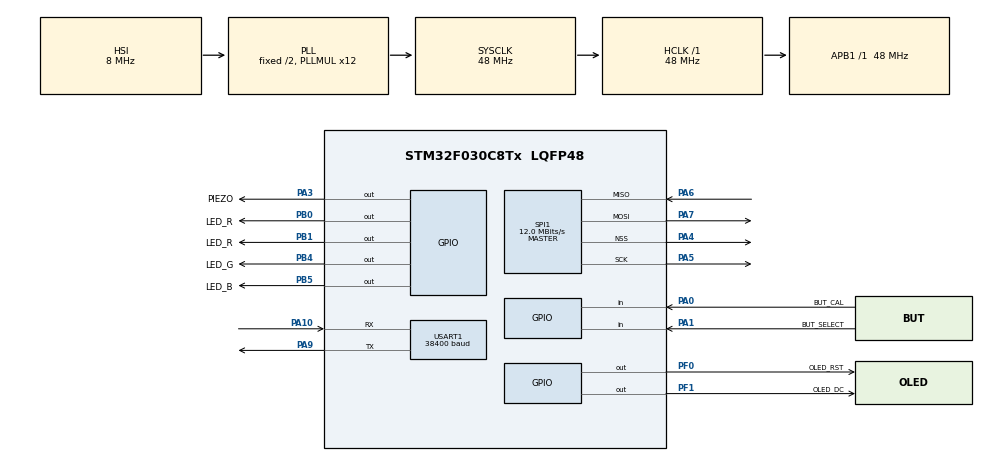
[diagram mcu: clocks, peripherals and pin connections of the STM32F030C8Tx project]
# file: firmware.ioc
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Mcu.Family=STM32F0
Mcu.Name=STM32F030C8Tx
Mcu.Package=LQFP48
NVIC.SPI1_IRQn=true\:0\:0\:false\:false\:true\:true\:true
NVIC.USART1_IRQn=true\:0\:0\:false\:false\:true\:true\:true
PA0.GPIO_Label=BUT_CAL
PA0.GPIO_PuPd=GPIO_PULLUP
PA0.Signal=GPIO_Input
PA1.GPIO_Label=BUT_SELECT
PA1.GPIO_PuPd=GPIO_PULLUP
PA1.Signal=GPIO_Input
PA10.Mode=Asynchronous
PA10.Signal=USART1_RX
PA13.Mode=Serial_Wire
PA13.Signal=SYS_SWDIO
PA14.Mode=Serial_Wire
PA14.Signal=SYS_SWCLK
PA3.GPIO_Label=PIEZO
PA3.GPIO_PuPd=GPIO_PULLDOWN
PA3.Signal=GPIO_Output
PA4.Mode=NSS_Signal_Hard_Output
PA4.Signal=SPI1_NSS
PA5.Mode=Full_Duplex_Master
PA5.Signal=SPI1_SCK
PA6.Mode=Full_Duplex_Master
PA6.Signal=SPI1_MISO
PA7.Mode=Full_Duplex_Master
PA7.Signal=SPI1_MOSI
PA9.Mode=Asynchronous
PA9.Signal=USART1_TX
PB0.GPIO_Label=LED_R
PB0.GPIO_PuPd=GPIO_PULLDOWN
PB0.Signal=GPIO_Output
PB1.GPIO_Label=LED_R
PB1.GPIO_PuPd=GPIO_PULLDOWN
PB1.Signal=GPIO_Output
PB4.GPIO_Label=LED_G
PB4.GPIO_PuPd=GPIO_PULLDOWN
PB4.Signal=GPIO_Output
PB5.GPIO_Label=LED_B
PB5.GPIO_PuPd=GPIO_PULLDOWN
PB5.Signal=GPIO_Output
PF0-OSC_IN.GPIO_Label=OLED_RST
PF0-OSC_IN.GPIO_PuPd=GPIO_PULLUP
PF0-OSC_IN.PinState=GPIO_PIN_SET
PF0-OSC_IN.Signal=GPIO_Output
PF1-OSC_OUT.GPIO_Label=OLED_DC
PF1-OSC_OUT.GPIO_PuPd=GPIO_PULLUP
PF1-OSC_OUT.PinState=GPIO_PIN_SET
PF1-OSC_OUT.Signal=GPIO_Output
ProjectManager.HeapSize=0x200
ProjectManager.StackSize=0x400
ProjectManager.TargetToolchain=Makefile
RCC.AHBFreq_Value=48000000
RCC.APB1Freq_Value=48000000
RCC.APB1TimFreq_Value=48000000
RCC.FLatency=FLASH_LATENCY_1
RCC.HCLKFreq_Value=48000000
RCC.PLLMUL=RCC_PLL_MUL12
RCC.SYSCLKFreq_VALUE=48000000
RCC.SYSCLKSource=RCC_SYSCLKSOURCE_PLLCLK
SPI1.BaudRatePrescaler=SPI_BAUDRATEPRESCALER_4
SPI1.CLKPhase=SPI_PHASE_1EDGE
SPI1.CLKPolarity=SPI_POLARITY_LOW
SPI1.CRCCalculation=SPI_CRCCALCULATION_DISABLE
SPI1.CalculateBaudRate=12.0 MBits/s
SPI1.DataSize=SPI_DATASIZE_8BIT
SPI1.Direction=SPI_DIRECTION_2LINES
SPI1.FirstBit=SPI_FIRSTBIT_MSB
SPI1.Mode=SPI_MODE_MASTER
SPI1.NSSPMode=SPI_NSS_PULSE_ENABLE
SPI1.TIMode=SPI_TIMODE_DISABLE
SPI1.VirtualNSS=VM_NSSHARD
SPI1.VirtualType=VM_MASTER
USART1.AutoBaudRateEnableParam=UART_ADVFEATURE_AUTOBAUDRATE_DISABLE
USART1.BaudRate=38400
USART1.DMADisableonRxErrorParam=ADVFEATURE_DMA_ENABLEONRXERROR
USART1.DataInvertParam=ADVFEATURE_DATAINV_DISABLE
USART1.MSBFirstParam=ADVFEATURE_MSBFIRST_DISABLE
USART1.Mode=MODE_TX_RX
USART1.OneBitSampling=UART_ONE_BIT_SAMPLE_DISABLE
USART1.OverSampling=UART_OVERSAMPLING_16
USART1.OverrunDisableParam=ADVFEATURE_OVERRUN_ENABLE
USART1.Parity=PARITY_NONE
USART1.RxPinLevelInvertParam=ADVFEATURE_RXINV_DISABLE
USART1.StopBits=STOPBITS_1
USART1.SwapParam=ADVFEATURE_SWAP_DISABLE
USART1.TxPinLevelInvertParam=ADVFEATURE_TXINV_DISABLE
USART1.VirtualMode-Asynchronous=VM_ASYNC
USART1.WordLength=WORDLENGTH_8B
board=custom

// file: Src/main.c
/* USER CODE BEGIN Header */
/**
  ******************************************************************************
  * @file           : main.c
  * @brief          : Main program body
  ******************************************************************************
  * @attention
  *
  * <h2><center>&copy; Copyright (c) 2020 STMicroelectronics.
  * All rights reserved.</center></h2>
  *
  * This software component is licensed by ST under BSD 3-Clause license,
  * the "License"; You may not use this file except in compliance with the
  * License. You may obtain a copy of the License at:
  *                        opensource.org/licenses/BSD-3-Clause
  *
  ******************************************************************************
  */
/* USER CODE END Header */

#include "main.h"
#include "spi.h"
#include "usart.h"
#include "gpio.h"

/* USER CODE BEGIN Includes */

#include "button.h"

/* USER CODE END Includes */

void SystemClock_Config(void);

int main(void)
{
  /* USER CODE BEGIN 1 */

  char input;

  /* USER CODE END 1 */

  /* MCU Configuration--------------------------------------------------------*/

  /* Reset of all peripherals, Initializes the Flash interface and the Systick. */
  HAL_Init();

  /* Configure the system clock */
  SystemClock_Config();

  /* Initialize all configured peripherals */
  MX_GPIO_Init();
  MX_SPI1_Init();
  MX_USART1_UART_Init();

  /* Infinite loop */
  while (1)
  {

    /* USER CODE BEGIN 3 */

    input = get_key(); // read pushbuttons

  }
  /* USER CODE END 3 */
}

void SystemClock_Config(void)
{
  RCC_OscInitTypeDef RCC_OscInitStruct = {0};
  RCC_ClkInitTypeDef RCC_ClkInitStruct = {0};
  RCC_PeriphCLKInitTypeDef PeriphClkInit = {0};

  /** Initializes the CPU, AHB and APB busses clocks
  */
  RCC_OscInitStruct.OscillatorType = RCC_OSCILLATORTYPE_HSI;
  RCC_OscInitStruct.HSIState = RCC_HSI_ON;
  RCC_OscInitStruct.HSICalibrationValue = RCC_HSICALIBRATION_DEFAULT;
  RCC_OscInitStruct.PLL.PLLState = RCC_PLL_ON;
  RCC_OscInitStruct.PLL.PLLSource = RCC_PLLSOURCE_HSI;
  RCC_OscInitStruct.PLL.PLLMUL = RCC_PLL_MUL12;
  RCC_OscInitStruct.PLL.PREDIV = RCC_PREDIV_DIV1;
  if (HAL_RCC_OscConfig(&RCC_OscInitStruct) != HAL_OK)
  {
    Error_Handler();
  }
  /** Initializes the CPU, AHB and APB busses clocks
  */
  RCC_ClkInitStruct.ClockType = RCC_CLOCKTYPE_HCLK|RCC_CLOCKTYPE_SYSCLK
                              |RCC_CLOCKTYPE_PCLK1;
  RCC_ClkInitStruct.SYSCLKSource = RCC_SYSCLKSOURCE_PLLCLK;
  RCC_ClkInitStruct.AHBCLKDivider = RCC_SYSCLK_DIV1;
  RCC_ClkInitStruct.APB1CLKDivider = RCC_HCLK_DIV1;

  if (HAL_RCC_ClockConfig(&RCC_ClkInitStruct, FLASH_LATENCY_1) != HAL_OK)
  {
    Error_Handler();
  }
  PeriphClkInit.PeriphClockSelection = RCC_PERIPHCLK_USART1;
  PeriphClkInit.Usart1ClockSelection = RCC_USART1CLKSOURCE_PCLK1;
  if (HAL_RCCEx_PeriphCLKConfig(&PeriphClkInit) != HAL_OK)
  {
    Error_Handler();
  }
}

void Error_Handler(void)
{
}

/************************ (C) COPYRIGHT STMicroelectronics *****END OF FILE****/
